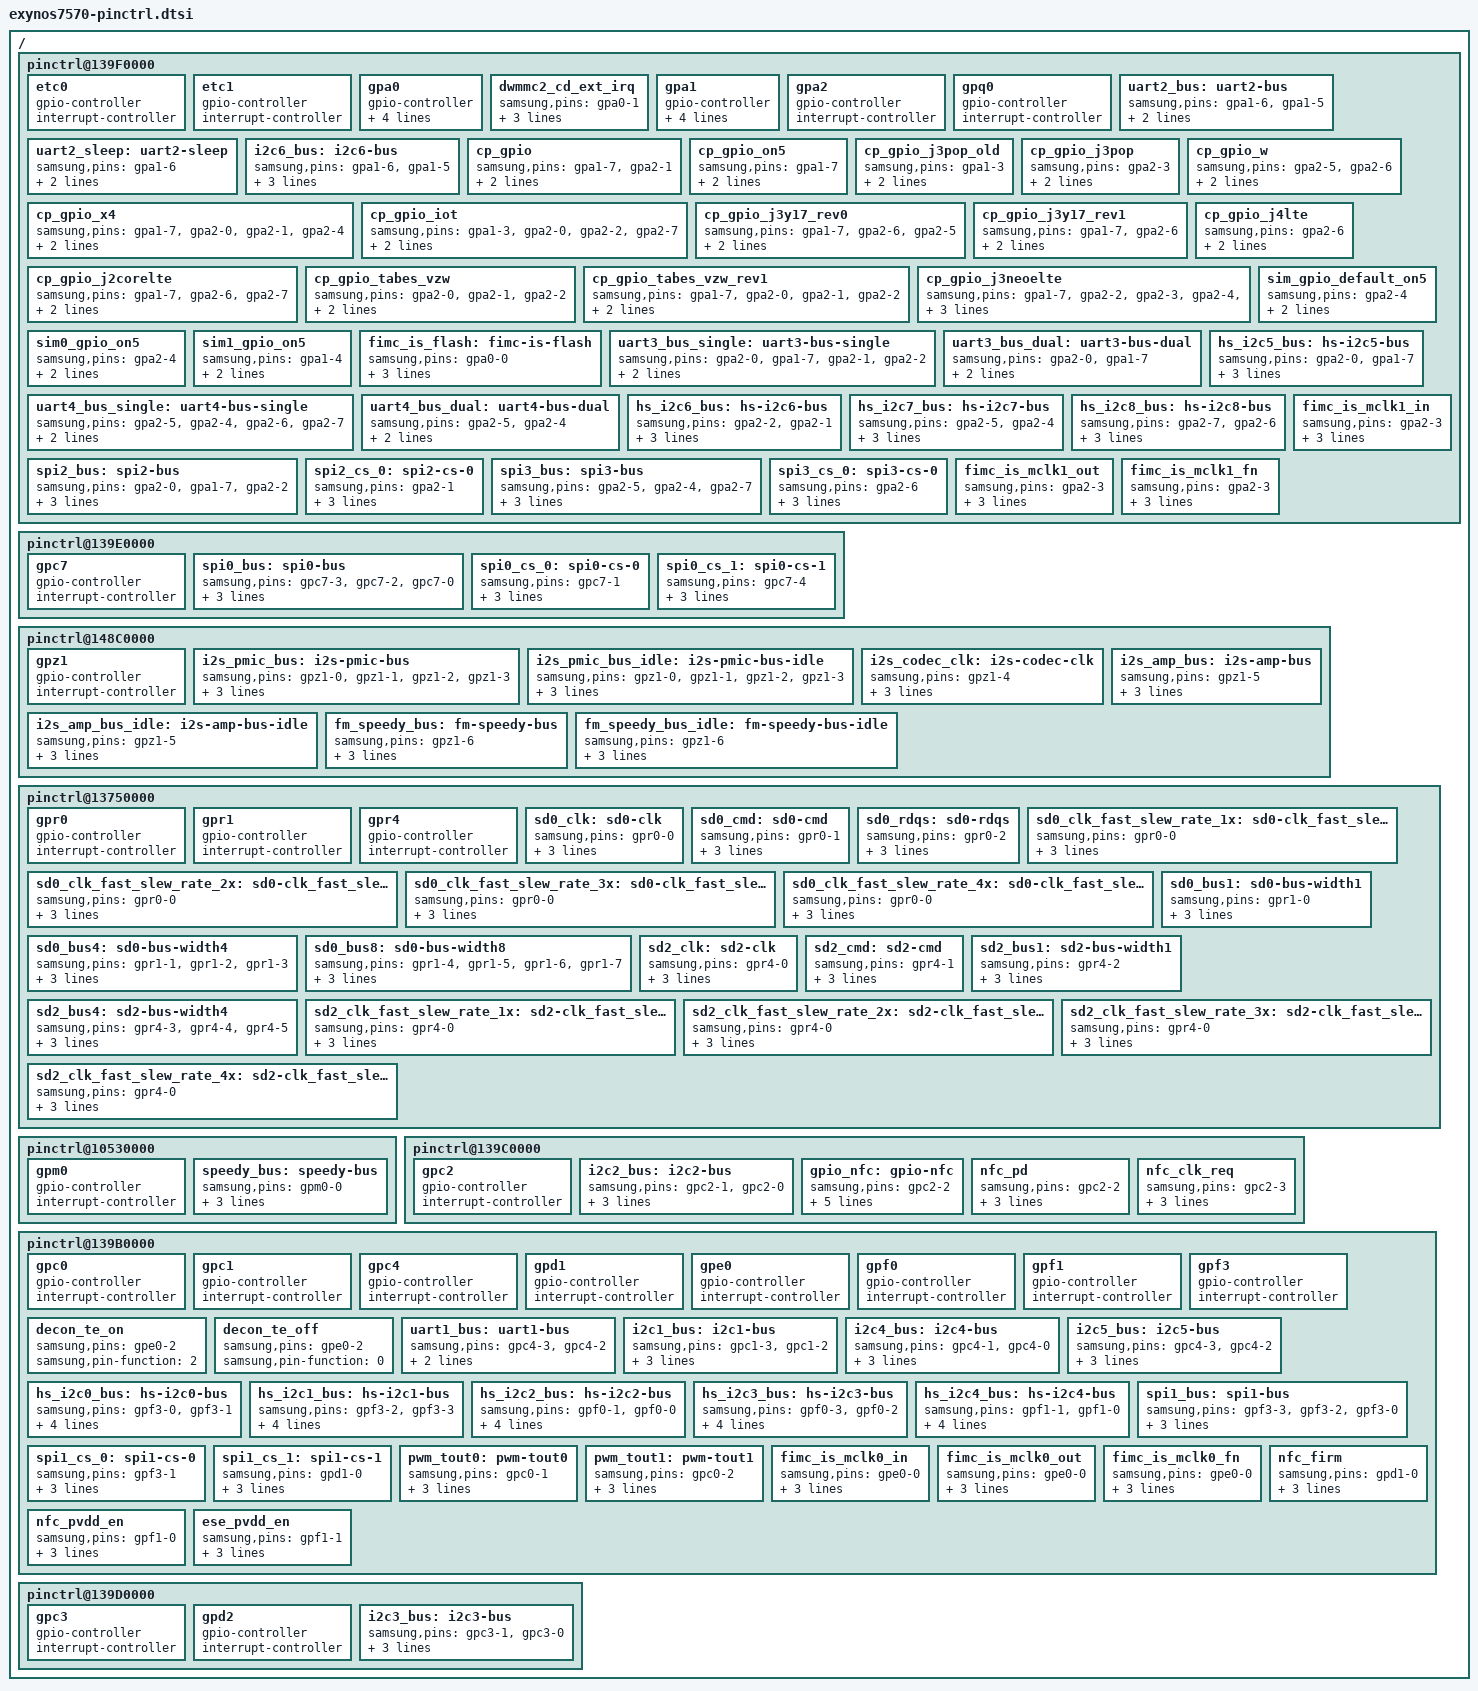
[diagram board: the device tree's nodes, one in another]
/*
 * Samsung's Exynos7570 SoC pin-mux and pin-config device tree source
 *
 * Copyright (c) 2014 Samsung Electronics Co., Ltd.
 *		http://www.samsung.com
 *
 * Samsung's Exynos7570 SoC pin-mux and pin-config options are listed as device
 * tree nodes are listed in this file.
 *
 * This program is free software; you can redistribute it and/or modify
 * it under the terms of the GNU General Public License version 2 as
 * published by the Free Software Foundation.
*/

/ {
	/* ALIVE */
	pinctrl@139F0000 {
		etc0: etc0 {
			gpio-controller;
			#gpio-cells = <2>;

			interrupt-controller;
			#interrupt-cells = <2>;
		};

		etc1: etc1 {
			gpio-controller;
			#gpio-cells = <2>;

			interrupt-controller;
			#interrupt-cells = <2>;
		};

		gpa0: gpa0 {
			gpio-controller;
			#gpio-cells = <2>;

			interrupt-controller;
			#interrupt-cells = <2>;
			interrupt-parent = <&gic>;
			interrupts = <0 0 0>, <0 1 0>, <0 2 0>, <0 3 0>,
				     <0 4 0>, <0 5 0>, <0 6 0>, <0 7 0>;
		};

		dwmmc2_cd_ext_irq: dwmmc2_cd_ext_irq {
			samsung,pins = "gpa0-1";
			samsung,pin-function = <0xf>;
			samsung,pin-pud = <0>;
			samsung,pin-drv = <4>;
		};

		gpa1: gpa1 {
			gpio-controller;
			#gpio-cells = <2>;

			interrupt-controller;
			#interrupt-cells = <3>;
			interrupt-parent = <&gic>;
			interrupts = <0 8 0>, <0 9 0>, <0 10 0>, <0 11 0>,
				     <0 12 0>, <0 13 0>, <0 14 0>, <0 15 0>;
		};

		gpa2: gpa2 {
			gpio-controller;
			#gpio-cells = <2>;

			interrupt-controller;
			#interrupt-cells = <2>;
		};

		gpq0: gpq0 {
			gpio-controller;
			#gpio-cells = <2>;

			interrupt-controller;
			#interrupt-cells = <2>;
		};

		/* UART_DEBUG */
		uart2_bus: uart2-bus {
			samsung,pins = "gpa1-6", "gpa1-5";
			samsung,pin-function = <3>;
			samsung,pin-pud = <0>;
		};

		uart2_sleep: uart2-sleep {
		        samsung,pins = "gpa1-6";
		        samsung,pin-function = <0>;
		        samsung,pin-pud = <1>;
		};

		/* I2C_SENSOR2 */
		i2c6_bus: i2c6-bus {
			samsung,pins = "gpa1-6", "gpa1-5";
			samsung,pin-function = <2>;
			samsung,pin-pud = <3>;
			samsung,pin-drv = <0>;
		};

		cp_gpio: cp_gpio {
			samsung,pins = "gpa1-7", "gpa2-1";
			samsung,pin-function = <4>;
			samsung,pin-pud = <0>;
		};

		cp_gpio_on5: cp_gpio_on5 {
			samsung,pins = "gpa1-7";
			samsung,pin-function = <4>;
			samsung,pin-pud = <0>;
		};

		cp_gpio_j3pop_old: cp_gpio_j3pop_old {
			samsung,pins = "gpa1-3";
			samsung,pin-function = <4>;
			samsung,pin-pud = <0>;
		};
		
		cp_gpio_j3pop: cp_gpio_j3pop {
			samsung,pins = "gpa2-3";
			samsung,pin-function = <4>;
			samsung,pin-pud = <0>;
		};
		
		cp_gpio_x4: cp_gpio_x4 {
			samsung,pins = "gpa1-7", "gpa2-0", "gpa2-1", "gpa2-4";
			samsung,pin-function = <4>;
			samsung,pin-pud = <0>;
		};

		cp_gpio_w: cp_gpio_w {
			samsung,pins = "gpa2-5", "gpa2-6";
			samsung,pin-function = <4>;
			samsung,pin-pud = <0>;
		};

		cp_gpio_iot: cp_gpio_iot {
			samsung,pins = "gpa1-3", "gpa2-0", "gpa2-2", "gpa2-7";
			samsung,pin-function = <4>;
			samsung,pin-pud = <0>;
		};
		
		cp_gpio_j3y17_rev0: cp_gpio_j3y17_rev0 {
			samsung,pins = "gpa1-7", "gpa2-6", "gpa2-5";
			samsung,pin-function = <4>;
			samsung,pin-pud = <0>;
		};
		
		cp_gpio_j3y17_rev1: cp_gpio_j3y17_rev1 {
			samsung,pins = "gpa1-7", "gpa2-6";
			samsung,pin-function = <4>;
			samsung,pin-pud = <0>;
		};
		
		cp_gpio_j4lte: cp_gpio_j4lte {
			samsung,pins = "gpa2-6";
			samsung,pin-function = <4>;
			samsung,pin-pud = <0>;
		};
		
		cp_gpio_j2corelte: cp_gpio_j2corelte {
			samsung,pins = "gpa1-7" , "gpa2-6" , "gpa2-7";
			samsung,pin-function = <4>;
			samsung,pin-pud = <0>;
		};
		
		cp_gpio_tabes_vzw: cp_gpio_tabes_vzw {
			samsung,pins = "gpa2-0", "gpa2-1", "gpa2-2";
			samsung,pin-function = <4>;
			samsung,pin-pud = <0>;
		};
		
		cp_gpio_tabes_vzw_rev1: cp_gpio_tabes_vzw_rev1 {
			samsung,pins = "gpa1-7", "gpa2-0", "gpa2-1", "gpa2-2";
			samsung,pin-function = <4>;
			samsung,pin-pud = <0>;
		};

		cp_gpio_j3neoelte: cp_gpio_j3neoelte {
			samsung,pins = "gpa1-7", "gpa2-2", "gpa2-3", "gpa2-4", "gpa2-5", "gpa2-6", "gpa2-7";
			samsung,pin-function = <4>;	// CP_GPIO
			samsung,pin-pud = <0>;
		};

		sim_gpio_default_on5: sim_gpio_default_on5 {
			samsung,pins = "gpa2-4";
			samsung,pin-function = <0>;
			samsung,pin-pud = <0>;
		};

		sim0_gpio_on5: sim0_gpio_on5 {
			samsung,pins = "gpa2-4";
			samsung,pin-function = <15>;
			samsung,pin-pud = <0>;
		};

		sim1_gpio_on5: sim1_gpio_on5 {
			samsung,pins = "gpa1-4";
			samsung,pin-function = <15>;
			samsung,pin-pud = <0>;
		};

		fimc_is_flash: fimc-is-flash {
			samsung,pins = "gpa0-0";
			samsung,pin-function = <1>;
			samsung,pin-pud = <0>;
			samsung,pin-drv = <0>;
		};

		/* UART_USI_0 (Single mode)*/
		uart3_bus_single: uart3-bus-single {
			samsung,pins = "gpa2-0", "gpa1-7", "gpa2-1", "gpa2-2";
			samsung,pin-function = <2>;
			samsung,pin-pud = <0>;
		};

		/* UART_USI_0 (Dual mode)*/
		uart3_bus_dual: uart3-bus-dual {
			samsung,pins = "gpa2-0", "gpa1-7";
			samsung,pin-function = <2>;
			samsung,pin-pud = <0>;
		};

		/* UART_USI_1 (Single mode)*/
		uart4_bus_single: uart4-bus-single {
			samsung,pins = "gpa2-5", "gpa2-4", "gpa2-6", "gpa2-7";
			samsung,pin-function = <2>;
			samsung,pin-pud = <0>;
		};

		/* UART_USI_1 (Dual mode)*/
		uart4_bus_dual: uart4-bus-dual {
			samsung,pins = "gpa2-5", "gpa2-4";
			samsung,pin-function = <2>;
			samsung,pin-pud = <0>;
		};

		/* USI_0_CH0_HSI2C */
		hs_i2c5_bus: hs-i2c5-bus {
			samsung,pins = "gpa2-0", "gpa1-7";
			samsung,pin-function = <2>;
			samsung,pin-pud = <3>;
			samsung,pin-drv = <0>;
		};

		/* USI_0_CH1_HSI2C */
		hs_i2c6_bus: hs-i2c6-bus {
			samsung,pins = "gpa2-2", "gpa2-1";
			samsung,pin-function = <2>;
			samsung,pin-pud = <3>;
			samsung,pin-drv = <0>;
		};

		/* USI_1_CH0_HSI2C */
		hs_i2c7_bus: hs-i2c7-bus {
			samsung,pins = "gpa2-5", "gpa2-4";
			samsung,pin-function = <2>;
			samsung,pin-pud = <3>;
			samsung,pin-drv = <0>;
		};

		/* USI_1_CH1_HSI2C */
		hs_i2c8_bus: hs-i2c8-bus {
			samsung,pins = "gpa2-7", "gpa2-6";
			samsung,pin-function = <2>;
			samsung,pin-pud = <3>;
			samsung,pin-drv = <0>;
		};

		/* SPI USI0 */
		spi2_bus: spi2-bus {
			samsung,pins = "gpa2-0", "gpa1-7", "gpa2-2";
			samsung,pin-function = <2>;
			samsung,pin-pud = <3>;
			samsung,pin-drv = <0>;
		};

		spi2_cs_0: spi2-cs-0 {
			samsung,pins = "gpa2-1";
			samsung,pin-function = <1>;
			samsung,pin-pud = <3>;
			samsung,pin-drv = <0>;
		};

		/* SPI USI1 */
		spi3_bus: spi3-bus {
			samsung,pins = "gpa2-5", "gpa2-4", "gpa2-7";
			samsung,pin-function = <2>;
			samsung,pin-pud = <3>;
			samsung,pin-drv = <0>;
		};

		spi3_cs_0: spi3-cs-0 {
			samsung,pins = "gpa2-6";
			samsung,pin-function = <1>;
			samsung,pin-pud = <3>;
			samsung,pin-drv = <0>;
		};

               fimc_is_mclk1_in: fimc_is_mclk1_in {
                       samsung,pins = "gpa2-3";
                       samsung,pin-function = <0>;
                       samsung,pin-pud = <0>;
                       samsung,pin-drv = <0>;
               };

               fimc_is_mclk1_out: fimc_is_mclk1_out {
                       samsung,pins = "gpa2-3";
                       samsung,pin-function = <1>;
                       samsung,pin-pud = <1>;
                       samsung,pin-drv = <2>;
               };

               fimc_is_mclk1_fn: fimc_is_mclk1_fn {
                       samsung,pins = "gpa2-3";
                       samsung,pin-function = <2>;
                       samsung,pin-pud = <0>;
                       samsung,pin-drv = <1>;
               };
	};

	/* ESE */
	pinctrl@139E0000 {
		gpc7: gpc7 {
			gpio-controller;
			#gpio-cells = <2>;

			interrupt-controller;
			#interrupt-cells = <2>;
		};

		/* SPI_ESE */
		spi0_bus: spi0-bus {
			samsung,pins = "gpc7-3", "gpc7-2", "gpc7-0";
			samsung,pin-function = <2>;
			samsung,pin-pud = <3>;
			samsung,pin-drv = <0>;
		};

		spi0_cs_0: spi0-cs-0 {
			samsung,pins = "gpc7-1";
			samsung,pin-function = <1>;
			samsung,pin-pud = <3>;
			samsung,pin-drv = <0>;
		};

		spi0_cs_1: spi0-cs-1 {
			samsung,pins = "gpc7-4";
			samsung,pin-function = <1>;
			samsung,pin-pud = <3>;
			samsung,pin-drv = <0>;
		};
	};

	/* DISPAUD */
	pinctrl@148C0000 {
		gpz1: gpz1 {
			gpio-controller;
			#gpio-cells = <2>;

			interrupt-controller;
			#interrupt-cells = <2>;
		};

		i2s_pmic_bus: i2s-pmic-bus {
			samsung,pins = "gpz1-0", "gpz1-1", "gpz1-2", "gpz1-3";
			samsung,pin-function = <2>;
			samsung,pin-pud = <1>;
			samsung,pin-drv = <0>;
		};

		i2s_pmic_bus_idle: i2s-pmic-bus-idle {
			samsung,pins = "gpz1-0", "gpz1-1", "gpz1-2", "gpz1-3";
			samsung,pin-function = <0>;
			samsung,pin-pud = <1>;
			samsung,pin-drv = <0>;
		};

		i2s_codec_clk: i2s-codec-clk {
			samsung,pins = "gpz1-4";
			samsung,pin-function = <2>;
			samsung,pin-pud = <1>;
			samsung,pin-drv = <0>;
		};
		i2s_amp_bus: i2s-amp-bus {
			samsung,pins = "gpz1-5";
			samsung,pin-function = <2>;
			samsung,pin-pud = <3>;
			samsung,pin-drv = <2>;
		};

		i2s_amp_bus_idle: i2s-amp-bus-idle {
			samsung,pins = "gpz1-5";
			samsung,pin-function = <0>;
			samsung,pin-pud = <3>;
			samsung,pin-drv = <2>;
		};
		fm_speedy_bus: fm-speedy-bus {
			samsung,pins = "gpz1-6";
			samsung,pin-function = <2>;
			samsung,pin-pud = <3>;
			samsung,pin-drv = <2>;
		};

		fm_speedy_bus_idle: fm-speedy-bus-idle {
			samsung,pins = "gpz1-6";
			samsung,pin-function = <0>;
			samsung,pin-pud = <3>;
			samsung,pin-drv = <2>;
		};
	};

	/* FSYS */
	pinctrl@13750000 {
		gpr0: gpr0 {
			gpio-controller;
			#gpio-cells = <2>;

			interrupt-controller;
			#interrupt-cells = <2>;
		};

		gpr1: gpr1 {
			gpio-controller;
			#gpio-cells = <2>;

			interrupt-controller;
			#interrupt-cells = <2>;
		};

		gpr4: gpr4 {
			gpio-controller;
			#gpio-cells = <2>;

			interrupt-controller;
			#interrupt-cells = <2>;
		};

		sd0_clk: sd0-clk {
			samsung,pins = "gpr0-0";
			samsung,pin-function = <2>;
			samsung,pin-pud = <0>;
			samsung,pin-drv = <2>;
		};

		sd0_cmd: sd0-cmd {
			samsung,pins = "gpr0-1";
			samsung,pin-function = <2>;
			samsung,pin-pud = <3>;
			samsung,pin-drv = <2>;
		};

		sd0_rdqs: sd0-rdqs {
			samsung,pins = "gpr0-2";
			samsung,pin-function = <2>;
			samsung,pin-pud = <1>;
			samsung,pin-drv = <2>;
		};

		sd0_clk_fast_slew_rate_1x: sd0-clk_fast_slew_rate_1x {
			samsung,pins = "gpr0-0";
			samsung,pin-function = <2>;
			samsung,pin-pud = <0>;
			samsung,pin-drv = <0>;
		};

		sd0_clk_fast_slew_rate_2x: sd0-clk_fast_slew_rate_2x {
			samsung,pins = "gpr0-0";
			samsung,pin-function = <2>;
			samsung,pin-pud = <0>;
			samsung,pin-drv = <1>;
		};

		sd0_clk_fast_slew_rate_3x: sd0-clk_fast_slew_rate_3x {
			samsung,pins = "gpr0-0";
			samsung,pin-function = <2>;
			samsung,pin-pud = <0>;
			samsung,pin-drv = <2>;
		};

		sd0_clk_fast_slew_rate_4x: sd0-clk_fast_slew_rate_4x {
			samsung,pins = "gpr0-0";
			samsung,pin-function = <2>;
			samsung,pin-pud = <0>;
			samsung,pin-drv = <3>;
		};

		sd0_bus1: sd0-bus-width1 {
			samsung,pins = "gpr1-0";
			samsung,pin-function = <2>;
			samsung,pin-pud = <3>;
			samsung,pin-drv = <2>;
		};

		sd0_bus4: sd0-bus-width4 {
			samsung,pins = "gpr1-1", "gpr1-2", "gpr1-3";
			samsung,pin-function = <2>;
			samsung,pin-pud = <3>;
			samsung,pin-drv = <2>;
		};

		sd0_bus8: sd0-bus-width8 {
			samsung,pins = "gpr1-4", "gpr1-5", "gpr1-6", "gpr1-7";
			samsung,pin-function = <2>;
			samsung,pin-pud = <3>;
			samsung,pin-drv = <2>;
		};

		sd2_clk: sd2-clk {
			samsung,pins = "gpr4-0";
			samsung,pin-function = <2>;
			samsung,pin-pud = <0>;
			samsung,pin-drv = <2>;
		};

		sd2_cmd: sd2-cmd {
			samsung,pins = "gpr4-1";
			samsung,pin-function = <2>;
			samsung,pin-pud = <3>;
			samsung,pin-drv = <2>;
		};

		sd2_bus1: sd2-bus-width1 {
			samsung,pins = "gpr4-2";
			samsung,pin-function = <2>;
			samsung,pin-pud = <3>;
			samsung,pin-drv = <2>;
		};

		sd2_bus4: sd2-bus-width4 {
			samsung,pins = "gpr4-3", "gpr4-4", "gpr4-5";
			samsung,pin-function = <2>;
			samsung,pin-pud = <3>;
			samsung,pin-drv = <2>;
		};

		sd2_clk_fast_slew_rate_1x: sd2-clk_fast_slew_rate_1x {
			samsung,pins = "gpr4-0";
			samsung,pin-function = <2>;
			samsung,pin-pud = <0>;
			samsung,pin-drv = <0>;
		};

		sd2_clk_fast_slew_rate_2x: sd2-clk_fast_slew_rate_2x {
			samsung,pins = "gpr4-0";
			samsung,pin-function = <2>;
			samsung,pin-pud = <0>;
			samsung,pin-drv = <1>;
		};

		sd2_clk_fast_slew_rate_3x: sd2-clk_fast_slew_rate_3x {
			samsung,pins = "gpr4-0";
			samsung,pin-function = <2>;
			samsung,pin-pud = <0>;
			samsung,pin-drv = <2>;
		};

		sd2_clk_fast_slew_rate_4x: sd2-clk_fast_slew_rate_4x {
			samsung,pins = "gpr4-0";
			samsung,pin-function = <2>;
			samsung,pin-pud = <0>;
			samsung,pin-drv = <3>;
		};
	};

	/* MIF */
	pinctrl@10530000 {
		gpm0: gpm0 {
			gpio-controller;
			#gpio-cells = <2>;

			interrupt-controller;
			#interrupt-cells = <2>;
		};

		speedy_bus: speedy-bus {
			samsung,pins = "gpm0-0";
			samsung,pin-function = <2>;
			samsung,pin-drv = <0>;
			samsung,pin-con-pdn = <3>;
		};
	};

	/* NFC */
	pinctrl@139C0000 {
		gpc2: gpc2 {
			gpio-controller;
			#gpio-cells = <2>;

			interrupt-controller;
			#interrupt-cells = <2>;
		};

		/* I2C_NFC */
		i2c2_bus: i2c2-bus {
			samsung,pins = "gpc2-1", "gpc2-0";
			samsung,pin-function = <2>;
			samsung,pin-pud = <3>;
			samsung,pin-drv = <0>;
		};

		gpio_nfc: gpio-nfc {
			samsung,pins = "gpc2-2";
			samsung,pin-function = <0x1>;
			samsung,pin-pud = <0>;
			samsung,pin-drv = <0>;
			samsung,pin-con-pdn = <3>;
			samsung,pin-val = <1>;
		};

		nfc_pd: nfc_pd {
			samsung,pins = "gpc2-2";
			samsung,pin-function = <2>;
			samsung,pin-pud = <3>;
			samsung,pin-drv = <0>;
		};

		nfc_clk_req: nfc_clk_req {
			samsung,pins = "gpc2-3";
			samsung,pin-function = <2>;
			samsung,pin-pud = <1>;
			samsung,pin-drv = <0>;
		};

	};

	/* TOP */
	pinctrl@139B0000 {
		gpc0: gpc0 {
			gpio-controller;
			#gpio-cells = <2>;

			interrupt-controller;
			#interrupt-cells = <2>;
		};

		gpc1: gpc1 {
			gpio-controller;
			#gpio-cells = <2>;

			interrupt-controller;
			#interrupt-cells = <2>;
		};

		gpc4: gpc4 {
			gpio-controller;
			#gpio-cells = <2>;

			interrupt-controller;
			#interrupt-cells = <2>;
		};

		gpd1: gpd1 {
			gpio-controller;
			#gpio-cells = <2>;

			interrupt-controller;
			#interrupt-cells = <2>;
		};

		gpe0: gpe0 {
			gpio-controller;
			#gpio-cells = <2>;

			interrupt-controller;
			#interrupt-cells = <2>;
		};

		gpf0: gpf0 {
			gpio-controller;
			#gpio-cells = <2>;

			interrupt-controller;
			#interrupt-cells = <2>;
		};

		gpf1: gpf1 {
			gpio-controller;
			#gpio-cells = <2>;

			interrupt-controller;
			#interrupt-cells = <2>;
		};

		gpf3: gpf3 {
			gpio-controller;
			#gpio-cells = <2>;

			interrupt-controller;
			#interrupt-cells = <2>;
		};

		/* TE SIGNAL */
		decon_te_on: decon_te_on {
			samsung,pins = "gpe0-2";
			samsung,pin-function = <2>;
		};

		decon_te_off: decon_te_off {
			samsung,pins = "gpe0-2";
			samsung,pin-function = <0>;
		};

		/* UART_SENSOR */
		uart1_bus: uart1-bus {
			samsung,pins = "gpc4-3", "gpc4-2";
			samsung,pin-function = <4>;
			samsung,pin-pud = <0>;
		};

		/* I2C_MUIC */
		i2c1_bus: i2c1-bus {
			samsung,pins = "gpc1-3", "gpc1-2";
			samsung,pin-function = <2>;
			samsung,pin-pud = <3>;
			samsung,pin-drv = <0>;
		};

		/* I2C_FUELGAUGE */
		i2c4_bus: i2c4-bus {
			samsung,pins = "gpc4-1", "gpc4-0";
			samsung,pin-function = <2>;
			samsung,pin-pud = <3>;
			samsung,pin-drv = <0>;
		};

		/* I2C_SENSOR1 */
		i2c5_bus: i2c5-bus {
			samsung,pins = "gpc4-3", "gpc4-2";
			samsung,pin-function = <2>;
			samsung,pin-pud = <3>;
			samsung,pin-drv = <0>;
		};

		/* HSI2C_MAINCAM */
		hs_i2c0_bus: hs-i2c0-bus {
			samsung,pins = "gpf3-0", "gpf3-1";
			samsung,pin-function = <3>;
			samsung,pin-pud = <3>;
			samsung,pin-drv = <0>;
			samsung,pin-con-pdn = <3>;
		};

		/* HSI2C_FRONTCAM */
		hs_i2c1_bus: hs-i2c1-bus {
			samsung,pins = "gpf3-2", "gpf3-3";
			samsung,pin-function = <3>;
			samsung,pin-pud = <3>;
			samsung,pin-drv = <0>;
			samsung,pin-con-pdn = <3>;
		};

		/* HSI2C_REARSENSOR */
		hs_i2c2_bus: hs-i2c2-bus {
			samsung,pins = "gpf0-1", "gpf0-0";
			samsung,pin-function = <2>;
			samsung,pin-pud = <0>;
			samsung,pin-drv = <0>;
			samsung,pin-con-pdn = <3>;
		};

		/* HSI2C_FRONTSENSOR */
		hs_i2c3_bus: hs-i2c3-bus {
			samsung,pins = "gpf0-3", "gpf0-2";
			samsung,pin-function = <2>;
			samsung,pin-pud = <0>;
			samsung,pin-drv = <0>;
			samsung,pin-con-pdn = <3>;
		};

		/* HSI2C_REARAF */
		hs_i2c4_bus: hs-i2c4-bus {
			samsung,pins = "gpf1-1", "gpf1-0";
			samsung,pin-function = <2>;
			samsung,pin-pud = <3>;
			samsung,pin-drv = <0>;
			samsung,pin-con-pdn = <3>;
		};

		/* SPI_REARFROM */
		spi1_bus: spi1-bus {
			samsung,pins = "gpf3-3", "gpf3-2", "gpf3-0";
			samsung,pin-function = <2>;
			samsung,pin-pud = <3>;
			samsung,pin-drv = <0>;
		};

		spi1_cs_0: spi1-cs-0 {
			samsung,pins = "gpf3-1";
			samsung,pin-function = <1>;
			samsung,pin-pud = <3>;
			samsung,pin-drv = <0>;
		};

		spi1_cs_1: spi1-cs-1 {
			samsung,pins = "gpd1-0";
			samsung,pin-function = <1>;
			samsung,pin-pud = <3>;
			samsung,pin-drv = <0>;
		};

		/* PWM */
		pwm_tout0: pwm-tout0 {
			samsung,pins = "gpc0-1";
			samsung,pin-function = <2>;
			samsung,pin-pud = <1>;
			samsung,pin-drv = <0>;
		};

		pwm_tout1: pwm-tout1 {
			samsung,pins = "gpc0-2";
			samsung,pin-function = <2>;
			samsung,pin-pud = <1>;
			samsung,pin-drv = <0>;
		};

		fimc_is_mclk0_in: fimc_is_mclk0_in {
			samsung,pins = "gpe0-0";
			samsung,pin-function = <0>;
			samsung,pin-pud = <0>;
			samsung,pin-drv = <0>;
		};

		fimc_is_mclk0_out: fimc_is_mclk0_out {
			samsung,pins = "gpe0-0";
			samsung,pin-function = <1>;
			samsung,pin-pud = <1>;
			samsung,pin-drv = <2>;
		};

		fimc_is_mclk0_fn: fimc_is_mclk0_fn {
			samsung,pins = "gpe0-0";
			samsung,pin-function = <2>;
			samsung,pin-pud = <0>;
			samsung,pin-drv = <1>;
		};

		nfc_firm: nfc_firm {
			samsung,pins = "gpd1-0";
			samsung,pin-function = <1>;
			samsung,pin-pud = <1>;
			samsung,pin-val = <0>;
		};

		nfc_pvdd_en: nfc_pvdd_en {
			samsung,pins = "gpf1-0";
			samsung,pin-function = <1>;
			samsung,pin-pud = <3>;
			samsung,pin-val = <0>;
		};
		ese_pvdd_en: ese_pvdd_en {
			samsung,pins = "gpf1-1";
			samsung,pin-function = <1>;
			samsung,pin-pud = <1>;
			samsung,pin-val = <0>;
		};
	};

	/* TOUCH */
	pinctrl@139D0000 {
		gpc3: gpc3 {
			gpio-controller;
			#gpio-cells = <2>;

			interrupt-controller;
			#interrupt-cells = <2>;
		};

		gpd2: gpd2 {
			gpio-controller;
			#gpio-cells = <2>;

			interrupt-controller;
			#interrupt-cells = <2>;
		};

		/* I2C_TSP */
		i2c3_bus: i2c3-bus {
			samsung,pins = "gpc3-1", "gpc3-0";
			samsung,pin-function = <2>;
			samsung,pin-pud = <3>;
			samsung,pin-drv = <0>;
		};
	};
};
